# LPC43xx register map
File version: 5
Registers are 32-bit, read-write, reset 0x0 unless marked. A register's access mark holds for its fields unless they carry their own. Offsets are from the block's base; [hi:lo] are bit positions; 'fields as' and 'values as' point back to an identical list.

## GIMA — Product name title=UM10503 Chapter title=LPC43xx Global Input Multiplexer Array (GIMA) Modification date=10/7/2011 Major revision=0 Minor revision=3
Base 0x400C7000
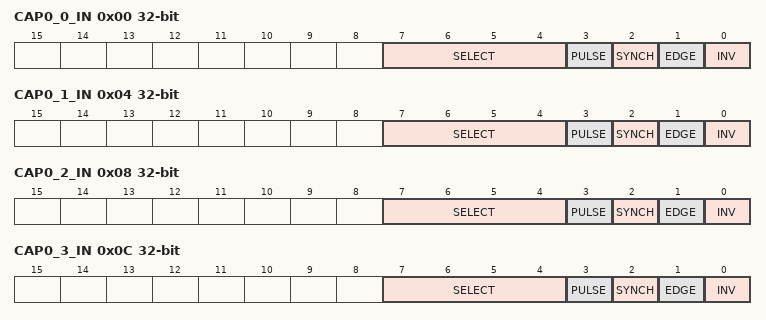
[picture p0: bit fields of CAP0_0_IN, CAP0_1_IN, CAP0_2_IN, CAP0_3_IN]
0x00 CAP0_0_IN — Timer 0 CAP0_0 capture input multiplexer (GIMA output 0)
  [7:4] SELECT — Select input. Values 0x3 to 0xF are reserved.
    0=CTIN_0; 1=SGPIO3; 2=T0_CAP0
  [3] PULSE — Enable single pulse generation.
    0=DISABLE_SINGLE_PULSE (Disable single pulse generation.); 1=ENABLE_SINGLE_PULSE_ (Enable single pulse generation.)
  [2] SYNCH — Enable synchronization
    0=DISABLE__SYNCHRONIZ (Disable synchronization.); 1=ENABLE__SYNCHRONIZA (Enable synchronization.)
  [1] EDGE — Enable rising edge detection
    0=NO_EDGE_DETECTION_; 1=RISING_EDGE_DETECTIO (Rising edge detection enabled.)
  [0] INV — Invert input
    0=NOT_INVERTED_; 1=INPUT_INVERTED_
0x04 CAP0_1_IN — Timer 0 CAP0_1 capture input multiplexer (GIMA output 1)
  [7:4] SELECT — Select input. Values 0x3 to 0xF are reserved.
    0=CTIN_1; 1=USART2_TX_ACTIVE; 2=T0_CAP1
  [3] PULSE — Enable single pulse generation.
    values as CAP0_0_IN.PULSE
  [2] SYNCH — Enable synchronization
    values as CAP0_0_IN.SYNCH
  [1] EDGE — Enable rising edge detection
    values as CAP0_0_IN.EDGE
  [0] INV — Invert input
    0=NOT_INVERTED_; 1=INPUT_INVERTED_
0x08 CAP0_2_IN — Timer 0 CAP0_2 capture input multiplexer (GIMA output 2)
  [7:4] SELECT — Select input. Values 0x3 to 0xF are reserved.
    0=CTIN_2; 1=SGPIO3_DIV; 2=T0_CAP2
  [3] PULSE — Enable single pulse generation.
    values as CAP0_0_IN.PULSE
  [2] SYNCH — Enable synchronization
    values as CAP0_0_IN.SYNCH
  [1] EDGE — Enable rising edge detection
    values as CAP0_0_IN.EDGE
  [0] INV — Invert input
    0=NOT_INVERTED_; 1=INPUT_INVERTED_
0x0C CAP0_3_IN — Timer 0 CAP0_3 capture input multiplexer (GIMA output 3)
  [7:4] SELECT — Select input. Values 0x3 to 0xF are reserved.
    0=CTOUT_15_OR_T3_MAT3; 1=T0_CAP3; 2=T3_MAT3
  [3] PULSE — Enable single pulse generation.
    values as CAP0_0_IN.PULSE
  [2] SYNCH — Enable synchronization
    values as CAP0_0_IN.SYNCH
  [1] EDGE — Enable rising edge detection
    values as CAP0_0_IN.EDGE
  [0] INV — Invert input
    0=NOT_INVERTED_; 1=INPUT_INVERTED_
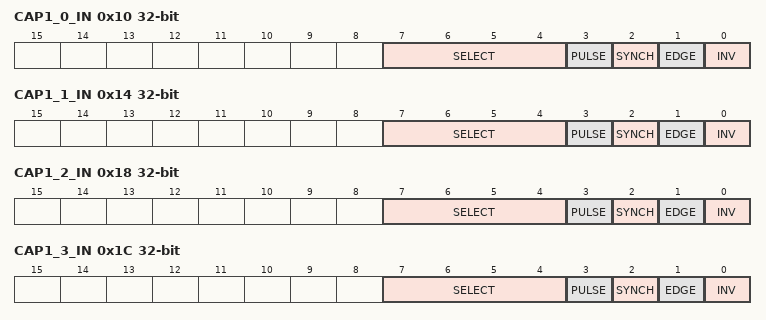
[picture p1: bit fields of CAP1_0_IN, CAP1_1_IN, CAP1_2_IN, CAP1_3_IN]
0x10 CAP1_0_IN — Timer 1 CAP1_0 capture input multiplexer (GIMA output 4)
  [7:4] SELECT — Select input. Values 0x3 to 0xF are reserved.
    0=CTIN_0; 1=SGPIO12; 2=T1_CAP0
  [3] PULSE — Enable single pulse generation.
    values as CAP0_0_IN.PULSE
  [2] SYNCH — Enable synchronization
    values as CAP0_0_IN.SYNCH
  [1] EDGE — Enable rising edge detection
    values as CAP0_0_IN.EDGE
  [0] INV — Invert input
    0=NOT_INVERTED_; 1=INPUT_INVERTED_
0x14 CAP1_1_IN — Timer 1 CAP1_1 capture input multiplexer (GIMA output 5)
  [7:4] SELECT — Select input. Values 0x3 to 0xF are reserved.
    0=CTIN_3; 1=USART0_TX_ACTIVE; 2=T1_CAP1
  [3] PULSE — Enable single pulse generation.
    values as CAP0_0_IN.PULSE
  [2] SYNCH — Enable synchronization
    values as CAP0_0_IN.SYNCH
  [1] EDGE — Enable rising edge detection
    values as CAP0_0_IN.EDGE
  [0] INV — Invert input
    0=NOT_INVERTED_; 1=INPUT_INVERTED_
0x18 CAP1_2_IN — Timer 1 CAP1_2 capture input multiplexer (GIMA output 6)
  [7:4] SELECT — Select input. Values 0x3 to 0xF are reserved.
    0=CTIN_4; 1=USART0_RX_ACTIVE; 2=T1_CAP2
  [3] PULSE — Enable single pulse generation.
    values as CAP0_0_IN.PULSE
  [2] SYNCH — Enable synchronization
    values as CAP0_0_IN.SYNCH
  [1] EDGE — Enable rising edge detection
    values as CAP0_0_IN.EDGE
  [0] INV — Invert input
    0=NOT_INVERTED_; 1=INPUT_INVERTED_
0x1C CAP1_3_IN — Timer 1 CAP1_3 capture input multiplexer (GIMA output 7)
  [7:4] SELECT — Select input. Values 0x3 to 0xF are reserved.
    0=CTOUT_3_OR_T0_MAT3; 1=T1_CAP3; 2=T0_MAT3
  [3] PULSE — Enable single pulse generation.
    values as CAP0_0_IN.PULSE
  [2] SYNCH — Enable synchronization
    values as CAP0_0_IN.SYNCH
  [1] EDGE — Enable rising edge detection
    values as CAP0_0_IN.EDGE
  [0] INV — Invert input
    0=NOT_INVERTED_; 1=INPUT_INVERTED_
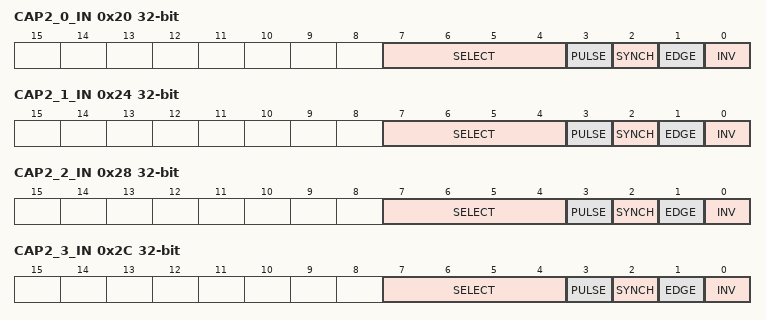
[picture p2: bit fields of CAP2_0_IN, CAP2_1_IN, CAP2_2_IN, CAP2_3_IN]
0x20 CAP2_0_IN — Timer 2 CAP2_0 capture input multiplexer (GIMA output 8)
  [7:4] SELECT — Select input. Values 0x4 to 0xF are reserved.
    0=CTIN_0; 1=SGPIO12_DIV; 2=T2_CAP0
  [3] PULSE — Enable single pulse generation.
    values as CAP0_0_IN.PULSE
  [2] SYNCH — Enable synchronization
    values as CAP0_0_IN.SYNCH
  [1] EDGE — Enable rising edge detection
    values as CAP0_0_IN.EDGE
  [0] INV — Invert input
    0=NOT_INVERTED_; 1=INPUT_INVERTED_
0x24 CAP2_1_IN — Timer 2 CAP2_1 capture input multiplexer (GIMA output 9)
  [7:4] SELECT — Select input. Values 0x4 to 0xF are reserved.
    0=CTIN_1; 1=USART2_TX_ACTIVE; 2=_I2S1_RX_MWS; 3=T2_CAP1
  [3] PULSE — Enable single pulse generation.
    values as CAP0_0_IN.PULSE
  [2] SYNCH — Enable synchronization
    values as CAP0_0_IN.SYNCH
  [1] EDGE — Enable rising edge detection
    values as CAP0_0_IN.EDGE
  [0] INV — Invert input
    0=NOT_INVERTED_; 1=INPUT_INVERTED_
0x28 CAP2_2_IN — Timer 2 CAP2_2 capture input multiplexer (GIMA output 10)
  [7:4] SELECT — Select input. Values 0x4 to 0xF are reserved.
    0=CTIN_5; 1=USART2_RX_ACTIVE; 2=_I2S1_TX_MWS; 3=T2_CAP2
  [3] PULSE — Enable single pulse generation.
    values as CAP0_0_IN.PULSE
  [2] SYNCH — Enable synchronization
    values as CAP0_0_IN.SYNCH
  [1] EDGE — Enable rising edge detection
    values as CAP0_0_IN.EDGE
  [0] INV — Invert input
    0=NOT_INVERTED_; 1=INPUT_INVERTED_
0x2C CAP2_3_IN — Timer 2 CAP2_3 capture input multiplexer (GIMA output 11)
  [7:4] SELECT — Select input. Values 0x3 to 0xF are reserved.
    0=CTOUT_7_OR_T1_MAT3; 1=T2_CAP3; 2=T1_MAT3
  [3] PULSE — Enable single pulse generation.
    values as CAP0_0_IN.PULSE
  [2] SYNCH — Enable synchronization
    values as CAP0_0_IN.SYNCH
  [1] EDGE — Enable rising edge detection
    values as CAP0_0_IN.EDGE
  [0] INV — Invert input
    0=NOT_INVERTED_; 1=INPUT_INVERTED_
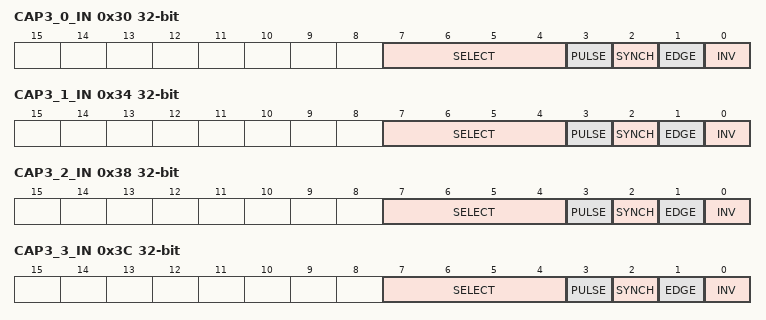
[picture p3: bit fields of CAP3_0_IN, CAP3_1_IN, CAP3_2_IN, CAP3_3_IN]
0x30 CAP3_0_IN — Timer 3 CAP3_0 capture input multiplexer (GIMA output 12)
  [7:4] SELECT — Select input. Values 0x3 to 0xF are reserved.
    0=CTIN_0; 1=I2S0_RX_MWS; 2=T3_CAP0
  [3] PULSE — Enable single pulse generation.
    values as CAP0_0_IN.PULSE
  [2] SYNCH — Enable synchronization
    values as CAP0_0_IN.SYNCH
  [1] EDGE — Enable rising edge detection
    values as CAP0_0_IN.EDGE
  [0] INV — Invert input
    0=NOT_INVERTED_; 1=INPUT_INVERTED_
0x34 CAP3_1_IN — Timer 3 CAP3_1 capture input multiplexer (GIMA output 13)
  [7:4] SELECT — Select input. Values 0x4 to 0xF are reserved.
    0=CTIN_6; 1=USART3_TX_ACTIVE; 2=TBD__I2S0_TX_MWS; 3=T3_CAP1
  [3] PULSE — Enable single pulse generation.
    values as CAP0_0_IN.PULSE
  [2] SYNCH — Enable synchronization
    values as CAP0_0_IN.SYNCH
  [1] EDGE — Enable rising edge detection
    values as CAP0_0_IN.EDGE
  [0] INV — Invert input
    0=NOT_INVERTED_; 1=INPUT_INVERTED_
0x38 CAP3_2_IN — Timer 3 CAP3_2 capture input multiplexer (GIMA output 14)
  [7:4] SELECT — Select input. Values 0x4 to 0xF are reserved.
    0=CTIN_7; 1=USART3_RX_ACTIVE; 2=SOF0_START_OF_FRAME (SOF0 (Start-Of-Frame USB0)); 3=T3_CAP2
  [3] PULSE — Enable single pulse generation.
    values as CAP0_0_IN.PULSE
  [2] SYNCH — Enable synchronization
    values as CAP0_0_IN.SYNCH
  [1] EDGE — Enable rising edge detection
    values as CAP0_0_IN.EDGE
  [0] INV — Invert input
    0=NOT_INVERTED_; 1=INPUT_INVERTED_
0x3C CAP3_3_IN — Timer 3 CAP3_3 capture input multiplexer (GIMA output 15)
  [7:4] SELECT — Select input. Values 0x4 to 0xF are reserved.
    0=CTOUT11_OR_T2_MAT3; 1=SOF1_START_OF_FRAME (SOF1 (Start-Of-Frame USB1)); 2=T3_CAP3; 3=T2_MAT3
  [3] PULSE — Enable single pulse generation.
    values as CAP0_0_IN.PULSE
  [2] SYNCH — Enable synchronization
    values as CAP0_0_IN.SYNCH
  [1] EDGE — Enable rising edge detection
    values as CAP0_0_IN.EDGE
  [0] INV — Invert input
    0=NOT_INVERTED_; 1=INPUT_INVERTED_
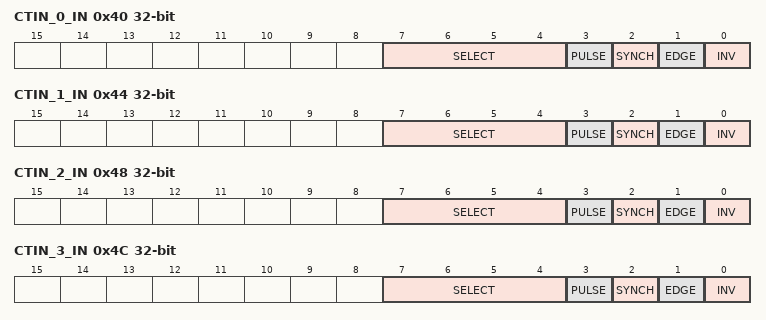
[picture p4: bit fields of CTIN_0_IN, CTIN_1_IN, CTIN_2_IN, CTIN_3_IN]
0x40 CTIN_0_IN — SCT CTIN_0 capture input multiplexer (GIMA output 16)
  [7:4] SELECT — Select input. Values 0x3 to 0xF are reserved.
    0=CTIN_0; 1=SGPIO3; 2=SGPIO3_DIV
  [3] PULSE — Enable single pulse generation.
    values as CAP0_0_IN.PULSE
  [2] SYNCH — Enable synchronization
    values as CAP0_0_IN.SYNCH
  [1] EDGE — Enable rising edge detection
    values as CAP0_0_IN.EDGE
  [0] INV — Invert input
    0=NOT_INVERTED_; 1=INPUT_INVERTED_
0x44 CTIN_1_IN — SCT CTIN_1 capture input multiplexer (GIMA output 17)
  [7:4] SELECT — Select input. Values 0x3 to 0xF are reserved.
    0=CTIN_1; 1=USART2_TX_ACTIVE; 2=SGPIO12
  [3] PULSE — Enable single pulse generation.
    values as CAP0_0_IN.PULSE
  [2] SYNCH — Enable synchronization
    values as CAP0_0_IN.SYNCH
  [1] EDGE — Enable rising edge detection
    values as CAP0_0_IN.EDGE
  [0] INV — Invert input
    0=NOT_INVERTED_; 1=INPUT_INVERTED_
0x48 CTIN_2_IN — SCT CTIN_2 capture input multiplexer (GIMA output 18)
  [7:4] SELECT — Select input. Values 0x3 to 0xF are reserved.
    0=CTIN_2; 1=SGPIO12; 2=SGPIO12_DIV
  [3] PULSE — Enable single pulse generation.
    values as CAP0_0_IN.PULSE
  [2] SYNCH — Enable synchronization
    values as CAP0_0_IN.SYNCH
  [1] EDGE — Enable rising edge detection
    values as CAP0_0_IN.EDGE
  [0] INV — Invert input
    0=NOT_INVERTED_; 1=INPUT_INVERTED_
0x4C CTIN_3_IN — SCT CTIN_3 capture input multiplexer (GIMA output 19)
  [7:4] SELECT — Select input. Values 0x4 to 0xF are reserved.
    0=CTIN_3; 1=USART0_TX_ACTIVE
  [3] PULSE — Enable single pulse generation.
    values as CAP0_0_IN.PULSE
  [2] SYNCH — Enable synchronization
    values as CAP0_0_IN.SYNCH
  [1] EDGE — Enable rising edge detection
    values as CAP0_0_IN.EDGE
  [0] INV — Invert input
    0=NOT_INVERTED_; 1=INPUT_INVERTED_
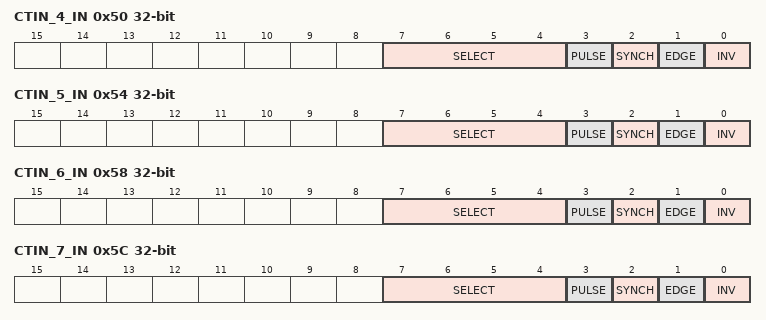
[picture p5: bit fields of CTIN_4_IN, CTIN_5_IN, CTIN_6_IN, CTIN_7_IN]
0x50 CTIN_4_IN — SCT CTIN_4 capture input multiplexer (GIMA output 20)
  [7:4] SELECT — Select input. Values 0x4 to 0xF are reserved.
    0=CTIN_4; 1=USART0_RX_ACTIVE; 2=_I2S1_RX_MWS1; 3=_I2S1_TX_MWS1
  [3] PULSE — Enable single pulse generation.
    values as CAP0_0_IN.PULSE
  [2] SYNCH — Enable synchronization
    values as CAP0_0_IN.SYNCH
  [1] EDGE — Enable rising edge detection
    values as CAP0_0_IN.EDGE
  [0] INV — Invert input
    0=NOT_INVERTED_; 1=INPUT_INVERTED_
0x54 CTIN_5_IN — SCT CTIN_5 capture input multiplexer (GIMA output 21)
  [7:4] SELECT — Select input. Values 0x3 to 0xF are reserved.
    0=CTIN_5; 1=USART2_RX_ACTIVE; 2=SGPIO12_DIV
  [3] PULSE — Enable single pulse generation.
    values as CAP0_0_IN.PULSE
  [2] SYNCH — Enable synchronization
    values as CAP0_0_IN.SYNCH
  [1] EDGE — Enable rising edge detection
    values as CAP0_0_IN.EDGE
  [0] INV — Invert input
    0=NOT_INVERTED_; 1=INPUT_INVERTED_
0x58 CTIN_6_IN — SCT CTIN_6 capture input multiplexer (GIMA output 22)
  [7:4] SELECT — Select input. Values 0x4 to 0xF are reserved.
    0=CTIN_6; 1=USART3_TX_ACTIVE; 2=_I2S0_RX_MWS; 3=_I2S0_TX_MWS
  [3] PULSE — Enable single pulse generation.
    values as CAP0_0_IN.PULSE
  [2] SYNCH — Enable synchronization
    values as CAP0_0_IN.SYNCH
  [1] EDGE — Enable rising edge detection
    values as CAP0_0_IN.EDGE
  [0] INV — Invert input
    0=NOT_INVERTED_; 1=INPUT_INVERTED_
0x5C CTIN_7_IN — SCT CTIN_7 capture input multiplexer (GIMA output 23)
  [7:4] SELECT — Select input. Values 0x4 to 0xF are reserved.
    0=CTIN_7; 1=USART3_RX_ACTIVE; 2=SOF0_START_OF_FRAME (SOF0 (Start-Of-Frame USB0)); 3=SOF1_START_OF_FRAME (SOF1 (Start-Of-Frame USB1))
  [3] PULSE — Enable single pulse generation.
    values as CAP0_0_IN.PULSE
  [2] SYNCH — Enable synchronization
    values as CAP0_0_IN.SYNCH
  [1] EDGE — Enable rising edge detection
    values as CAP0_0_IN.EDGE
  [0] INV — Invert input
    0=NOT_INVERTED_; 1=INPUT_INVERTED_
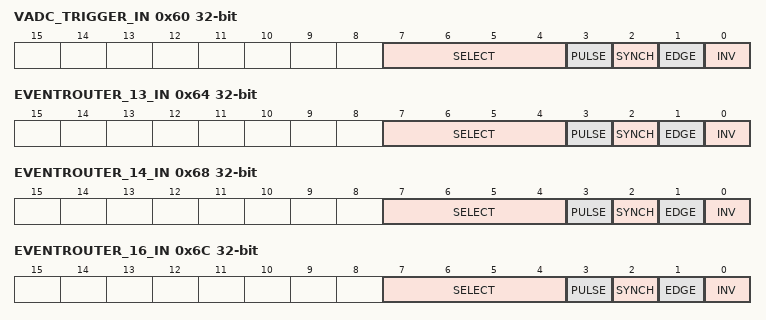
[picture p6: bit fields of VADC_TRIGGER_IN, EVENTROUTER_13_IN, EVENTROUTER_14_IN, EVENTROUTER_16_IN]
0x60 VADC_TRIGGER_IN — VADC trigger input multiplexer (GIMA output 24)
  [7:4] SELECT — Select input. Values 0xA to 0xF are reserved.
    0=GPIO6[28]; 1=GPIO5[3]; 2=SGPIO10; 3=SGPIO12; 5=MCOB2; 6=CTOUT_0_OR_T0_MAT0; 7=CTOUT_8_OR_T2_MAT0; 8=T0_MAT0; 9=T2_MAT0
  [3] PULSE — Enable single pulse generation.
    values as CAP0_0_IN.PULSE
  [2] SYNCH — Enable synchronization
    values as CAP0_0_IN.SYNCH
  [1] EDGE — Enable rising edge detection
    values as CAP0_0_IN.EDGE
  [0] INV — Invert input
    0=NOT_INVERTED_; 1=INPUT_INVERTED_
0x64 EVENTROUTER_13_IN — Event router input 13 multiplexer (GIMA output 25)
  [7:4] SELECT — Select input. Values 0x3 to 0xF are reserved.
    0=CTOUT_2_OR_T0_MAT2; 1=SGPIO3; 2=T0_MAT2
  [3] PULSE — Enable single pulse generation.
    values as CAP0_0_IN.PULSE
  [2] SYNCH — Enable synchronization
    values as CAP0_0_IN.SYNCH
  [1] EDGE — Enable rising edge detection
    values as CAP0_0_IN.EDGE
  [0] INV — Invert input
    0=NOT_INVERTED_; 1=INPUT_INVERTED_
0x68 EVENTROUTER_14_IN — Event router input 14 multiplexer (GIMA output 26)
  [7:4] SELECT — Select input. Values 0x3 to 0xF are reserved.
    0=CTOUT_6_OR_T1_MAT2; 1=SGPIO12; 2=T1_MAT2
  [3] PULSE — Enable single pulse generation.
    values as CAP0_0_IN.PULSE
  [2] SYNCH — Enable synchronization
    values as CAP0_0_IN.SYNCH
  [1] EDGE — Enable rising edge detection
    values as CAP0_0_IN.EDGE
  [0] INV — Invert input
    0=NOT_INVERTED_; 1=INPUT_INVERTED_
0x6C EVENTROUTER_16_IN — Event router input 16 multiplexer (GIMA output 27)
  [7:4] SELECT — Select input. Values 0x2 to 0xF are reserved.
    0=CTOUT_14_OR_T3_MAT2; 1=T3_MAT2
  [3] PULSE — Enable single pulse generation.
    values as CAP0_0_IN.PULSE
  [2] SYNCH — Enable synchronization
    values as CAP0_0_IN.SYNCH
  [1] EDGE — Enable rising edge detection
    values as CAP0_0_IN.EDGE
  [0] INV — Invert input
    0=NOT_INVERTED_; 1=INPUT_INVERTED_
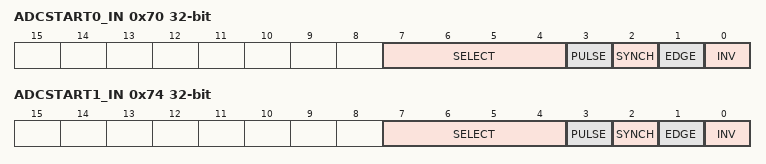
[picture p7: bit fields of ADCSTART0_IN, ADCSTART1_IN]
0x70 ADCSTART0_IN — ADC start0 input multiplexer (GIMA output 28)
  [7:4] SELECT — Select input. Values 0x2 to 0xF are reserved.
    0=CTOUT_15_OR_T3_MAT3; 1=T0_MAT0
  [3] PULSE — Enable single pulse generation.
    values as CAP0_0_IN.PULSE
  [2] SYNCH — Enable synchronization
    values as CAP0_0_IN.SYNCH
  [1] EDGE — Enable rising edge detection
    values as CAP0_0_IN.EDGE
  [0] INV — Invert input
    0=NOT_INVERTED_; 1=INPUT_INVERTED_
0x74 ADCSTART1_IN — ADC start1 input multiplexer (GIMA output 29)
  [7:4] SELECT — Select input. Values 0x2 to 0xF are reserved.
    0=CTOUT_8_OR_T2_MAT0; 1=T2_MAT0
  [3] PULSE — Enable single pulse generation.
    values as CAP0_0_IN.PULSE
  [2] SYNCH — Enable synchronization
    values as CAP0_0_IN.SYNCH
  [1] EDGE — Enable rising edge detection
    values as CAP0_0_IN.EDGE
  [0] INV — Invert input
    0=NOT_INVERTED_; 1=INPUT_INVERTED_
